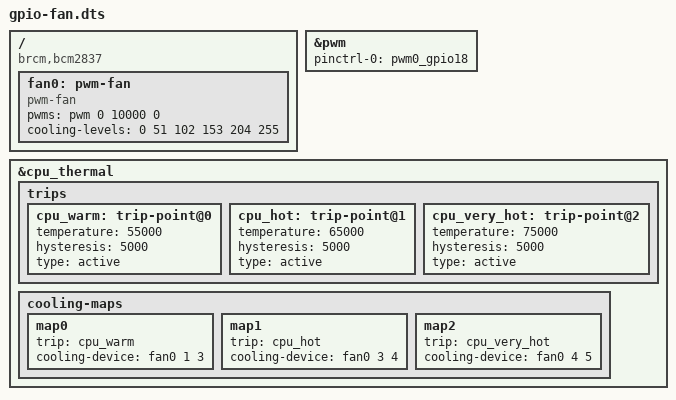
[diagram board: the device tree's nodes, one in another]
/dts-v1/;
/plugin/;

/ {
    compatible = "brcm,bcm2837";

    fragment@0 {
        target = <&pwm>;
        __overlay__ {
            pinctrl-names = "default";
            pinctrl-0 = <&pwm0_gpio18>;
            status = "okay";
        };
    };

    fragment@1 {
        target-path = "/";
        __overlay__ {
            fan0: pwm-fan {
                compatible = "pwm-fan";
                pwms = <&pwm 0 10000 0>; /* PWM channel 0, 10ms period, normal polarity */
                #cooling-cells = <2>;
                
                /* Define cooling levels (0-255) for different PWM duty cycles */
                /* 0=0%, 51=20%, 102=40%, 153=60%, 204=80%, 255=100% */
                cooling-levels = <0 51 102 153 204 255>;
            };
        };
    };

    fragment@2 {
        target = <&cpu_thermal>;
        __overlay__ {
            trips {
                cpu_warm: trip-point@0 {
                    temperature = <55000>;  /* 55°C - start spinning slowly */
                    hysteresis = <5000>;    /* 5°C hysteresis */
                    type = "active";
                };
                cpu_hot: trip-point@1 {
                    temperature = <65000>;  /* 65°C - medium speed */
                    hysteresis = <5000>;
                    type = "active";
                };
                cpu_very_hot: trip-point@2 {
                    temperature = <75000>;  /* 75°C - full speed */
                    hysteresis = <5000>;
                    type = "active";
                };
            };
            cooling-maps {
                map0 {
                    trip = <&cpu_warm>;
                    cooling-device = <&fan0 1 3>; /* Use cooling levels 1-3 (20%-60%) */
                };
                map1 {
                    trip = <&cpu_hot>;
                    cooling-device = <&fan0 3 4>; /* Use cooling levels 3-4 (60%-80%) */
                };
                map2 {
                    trip = <&cpu_very_hot>;
                    cooling-device = <&fan0 4 5>; /* Use cooling levels 4-5 (80%-100%) */
                };
            };
        };
    };
};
